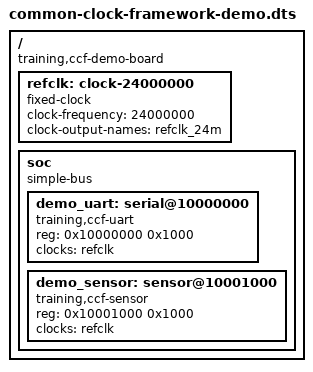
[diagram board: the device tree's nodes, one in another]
/dts-v1/;

/ {
	compatible = "training,ccf-demo-board";
	#address-cells = <1>;
	#size-cells = <1>;

	refclk: clock-24000000 {
		compatible = "fixed-clock";
		#clock-cells = <0>;
		clock-frequency = <24000000>;
		clock-output-names = "refclk_24m";
	};

	soc {
		compatible = "simple-bus";
		#address-cells = <1>;
		#size-cells = <1>;
		ranges;

		demo_uart: serial@10000000 {
			compatible = "training,ccf-uart";
			reg = <0x10000000 0x1000>;
			clocks = <&refclk>;
			clock-names = "core";
			status = "okay";
		};

		demo_sensor: sensor@10001000 {
			compatible = "training,ccf-sensor";
			reg = <0x10001000 0x1000>;
			clocks = <&refclk>;
			clock-names = "xclk";
			status = "okay";
		};
	};
};
